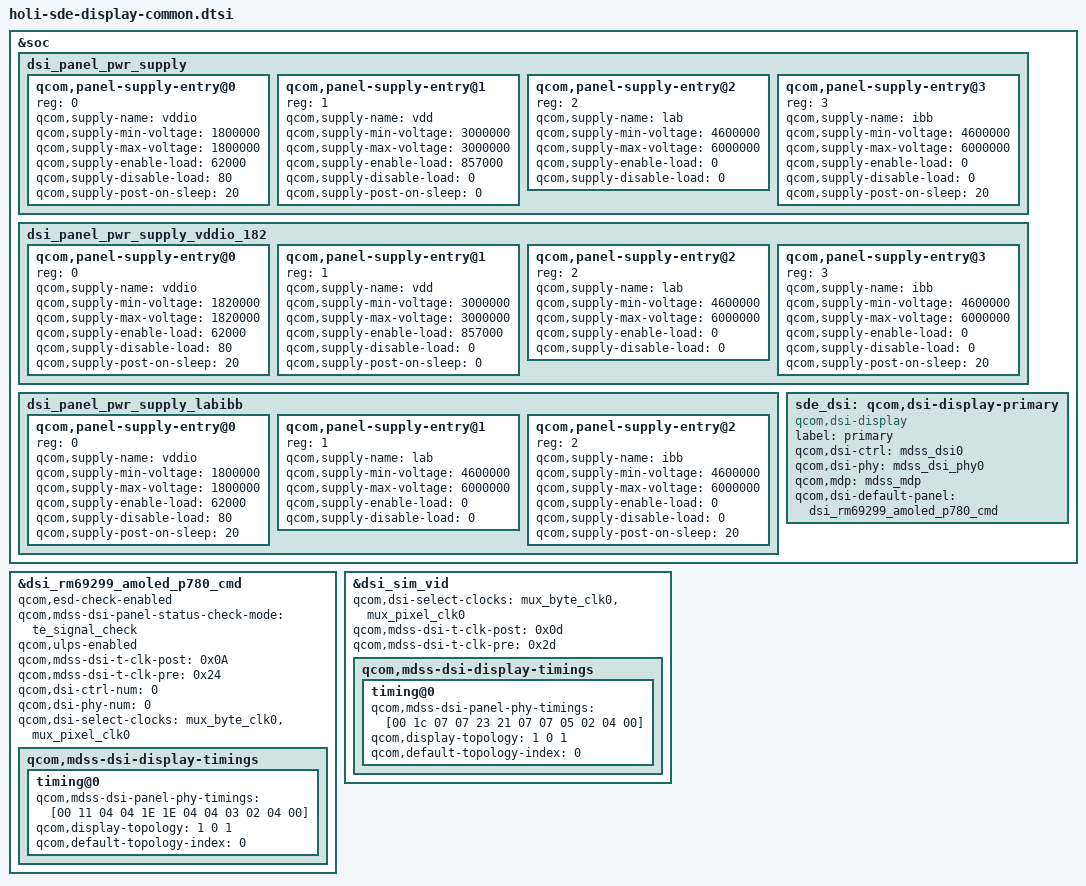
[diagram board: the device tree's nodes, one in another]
//add p780 RM69299 LCD IC begin:
#include "dsi-panel-rm69299-amoled-p780-cmd.dtsi"
//add p780 RM69299 LCD IC end
#include "dsi-panel-sim-video.dtsi"
#include <dt-bindings/clock/mdss-10nm-pll-clk.h>

&soc {
	dsi_panel_pwr_supply: dsi_panel_pwr_supply {
		#address-cells = <1>;
		#size-cells = <0>;

		qcom,panel-supply-entry@0 {
			reg = <0>;
			qcom,supply-name = "vddio";
			qcom,supply-min-voltage = <1800000>;
			qcom,supply-max-voltage = <1800000>;
			qcom,supply-enable-load = <62000>;
			qcom,supply-disable-load = <80>;
			qcom,supply-post-on-sleep = <20>;
		};

		qcom,panel-supply-entry@1 {
			reg = <1>;
			qcom,supply-name = "vdd";
			qcom,supply-min-voltage = <3000000>;
			qcom,supply-max-voltage = <3000000>;
			qcom,supply-enable-load = <857000>;
			qcom,supply-disable-load = <0>;
			qcom,supply-post-on-sleep = <0>;
		};

		qcom,panel-supply-entry@2 {
			reg = <2>;
			qcom,supply-name = "lab";
			qcom,supply-min-voltage = <4600000>;
			qcom,supply-max-voltage = <6000000>;
			qcom,supply-enable-load = <0>;
			qcom,supply-disable-load = <0>;
		};

		qcom,panel-supply-entry@3 {
			reg = <3>;
			qcom,supply-name = "ibb";
			qcom,supply-min-voltage = <4600000>;
			qcom,supply-max-voltage = <6000000>;
			qcom,supply-enable-load = <0>;
			qcom,supply-disable-load = <0>;
			qcom,supply-post-on-sleep = <20>;
		};
	};
	
	dsi_panel_pwr_supply_vddio_182: dsi_panel_pwr_supply_vddio_182 {
		#address-cells = <1>;
		#size-cells = <0>;

		qcom,panel-supply-entry@0 {
			reg = <0>;
			qcom,supply-name = "vddio";
			qcom,supply-min-voltage = <1820000>;
			qcom,supply-max-voltage = <1820000>;
			qcom,supply-enable-load = <62000>;
			qcom,supply-disable-load = <80>;
			qcom,supply-post-on-sleep = <20>;
		};

		qcom,panel-supply-entry@1 {
			reg = <1>;
			qcom,supply-name = "vdd";
			qcom,supply-min-voltage = <3000000>;
			qcom,supply-max-voltage = <3000000>;
			qcom,supply-enable-load = <857000>;
			qcom,supply-disable-load = <0>;
			qcom,supply-post-on-sleep = <0>;
		};

		qcom,panel-supply-entry@2 {
			reg = <2>;
			qcom,supply-name = "lab";
			qcom,supply-min-voltage = <4600000>;
			qcom,supply-max-voltage = <6000000>;
			qcom,supply-enable-load = <0>;
			qcom,supply-disable-load = <0>;
		};

		qcom,panel-supply-entry@3 {
			reg = <3>;
			qcom,supply-name = "ibb";
			qcom,supply-min-voltage = <4600000>;
			qcom,supply-max-voltage = <6000000>;
			qcom,supply-enable-load = <0>;
			qcom,supply-disable-load = <0>;
			qcom,supply-post-on-sleep = <20>;
		};
	};

	dsi_panel_pwr_supply_labibb: dsi_panel_pwr_supply_labibb {
		#address-cells = <1>;
		#size-cells = <0>;

		qcom,panel-supply-entry@0 {
			reg = <0>;
			qcom,supply-name = "vddio";
			qcom,supply-min-voltage = <1800000>;
			qcom,supply-max-voltage = <1800000>;
			qcom,supply-enable-load = <62000>;
			qcom,supply-disable-load = <80>;
			qcom,supply-post-on-sleep = <20>;
		};

		qcom,panel-supply-entry@1 {
			reg = <1>;
			qcom,supply-name = "lab";
			qcom,supply-min-voltage = <4600000>;
			qcom,supply-max-voltage = <6000000>;
			qcom,supply-enable-load = <0>;
			qcom,supply-disable-load = <0>;
		};

		qcom,panel-supply-entry@2 {
			reg = <2>;
			qcom,supply-name = "ibb";
			qcom,supply-min-voltage = <4600000>;
			qcom,supply-max-voltage = <6000000>;
			qcom,supply-enable-load = <0>;
			qcom,supply-disable-load = <0>;
			qcom,supply-post-on-sleep = <20>;
		};
	};

	sde_dsi: qcom,dsi-display-primary {
		compatible = "qcom,dsi-display";
		label = "primary";

		qcom,dsi-ctrl = <&mdss_dsi0>;
		qcom,dsi-phy = <&mdss_dsi_phy0>;

		qcom,mdp = <&mdss_mdp>;
		qcom,dsi-default-panel = <&dsi_rm69299_amoled_p780_cmd>;
	};
};

//add p780 RM69299 LCD IC begin:
&dsi_rm69299_amoled_p780_cmd {
	qcom,esd-check-enabled;
	qcom,mdss-dsi-panel-status-check-mode = "te_signal_check";
////	qcom,mdss-dsi-panel-status-command = [06 01 00 01 00 00 01 0a];
////	qcom,mdss-dsi-panel-status-command-state = "dsi_hs_mode";
////	qcom,mdss-dsi-panel-status-value = <0x9c>;
//	qcom,mdss-dsi-panel-on-check-value = <0x9c>;
////	qcom,mdss-dsi-panel-status-read-length = <1>;
//	qcom,dsi-supported-dfps-list = <60 55 48>;
//	qcom,mdss-dsi-pan-enable-dynamic-fps;
//	qcom,mdss-dsi-pan-fps-update = "dfps_immediate_porch_mode_vfp";
//	qcom,dsi-dyn-clk-enable;
//	qcom,dsi-dyn-clk-list =
//		<950938560 935089584 939051832 943014072 946976320>;
        qcom,ulps-enabled;
	qcom,mdss-dsi-t-clk-post = <0x0A>;
	qcom,mdss-dsi-t-clk-pre = <0x24>;
	qcom,dsi-ctrl-num = <0>;
	qcom,dsi-phy-num = <0>;
	qcom,dsi-select-clocks = "mux_byte_clk0", "mux_pixel_clk0";
	qcom,mdss-dsi-display-timings {
		timing@0{
			qcom,mdss-dsi-panel-phy-timings = [00 11 04 04 1E 1E 04
				04 03 02 04 00];
			qcom,display-topology = <1 0 1>;
			qcom,default-topology-index = <0>;
		};
	};
};
//add p780 RM69299 LCD IC end

&dsi_sim_vid {
	qcom,dsi-select-clocks = "mux_byte_clk0", "mux_pixel_clk0";
	qcom,mdss-dsi-t-clk-post = <0x0d>;
	qcom,mdss-dsi-t-clk-pre = <0x2d>;
	qcom,mdss-dsi-display-timings {
		timing@0 {
			qcom,mdss-dsi-panel-phy-timings = [00 1c 07 07 23 21 07
				07 05 02 04 00];
			qcom,display-topology = <1 0 1>;
			qcom,default-topology-index = <0>;
		};
	};
};

